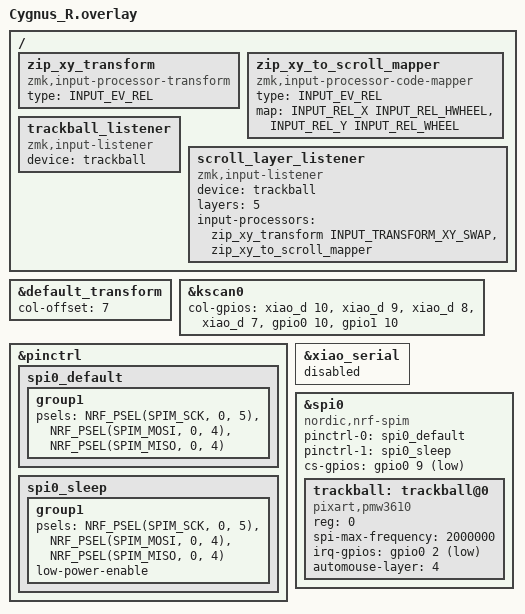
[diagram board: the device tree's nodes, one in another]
#include <dt-bindings/zmk/input_transform.h>
#include <dt-bindings/zmk/pointers.h>
#include <zephyr/dt-bindings/input/input-event-codes.h>
#include "Cygnus.dtsi"

&default_transform {
    col-offset = <7>;
};

&kscan0 {
    col-gpios
        = <&xiao_d 10 GPIO_ACTIVE_HIGH>
        , <&xiao_d 9 GPIO_ACTIVE_HIGH> 
        , <&xiao_d 8 GPIO_ACTIVE_HIGH> 
        , <&xiao_d 7 GPIO_ACTIVE_HIGH> 
        , <&gpio0 10 GPIO_ACTIVE_HIGH>
        , <&gpio1 10 GPIO_ACTIVE_HIGH>
        ;
};

/ {
    zip_xy_transform: zip_xy_transform {
        compatible = "zmk,input-processor-transform";
        #input-processor-cells = <1>;
        type = <INPUT_EV_REL>;
    };

    zip_xy_to_scroll_mapper: zip_xy_to_scroll_mapper {
        compatible = "zmk,input-processor-code-mapper";
        #input-processor-cells = <0>;
        type = <INPUT_EV_REL>;
        map = <INPUT_REL_X INPUT_REL_HWHEEL>, <INPUT_REL_Y INPUT_REL_WHEEL>;
    };

    trackball_listener {
        compatible = "zmk,input-listener";
        device = <&trackball>;
    };

    scroll_layer_listener {
        compatible = "zmk,input-listener";
        device = <&trackball>;
        layers = <5>;

        input-processors =
            <&zip_xy_transform INPUT_TRANSFORM_XY_SWAP>,
            <&zip_xy_to_scroll_mapper>;
    };
};

&pinctrl {
    spi0_default: spi0_default {
        group1 {
            psels = <NRF_PSEL(SPIM_SCK, 0, 5)>,
                <NRF_PSEL(SPIM_MOSI, 0, 4)>,
                <NRF_PSEL(SPIM_MISO, 0, 4)>;
        };
    };

    spi0_sleep: spi0_sleep {
        group1 {
            psels = <NRF_PSEL(SPIM_SCK, 0, 5)>,
                <NRF_PSEL(SPIM_MOSI, 0, 4)>,
                <NRF_PSEL(SPIM_MISO, 0, 4)>;
            low-power-enable;
        };
    };
};

&xiao_serial { status = "disabled"; };

&spi0 {
    status = "okay";
    compatible = "nordic,nrf-spim";
    pinctrl-0 = <&spi0_default>;
    pinctrl-1 = <&spi0_sleep>;
    pinctrl-names = "default", "sleep";
    cs-gpios = <&gpio0 9 GPIO_ACTIVE_LOW>;

    trackball: trackball@0 {
        status = "okay";
        compatible = "pixart,pmw3610";
        reg = <0>;
        spi-max-frequency = <2000000>;
        irq-gpios = <&gpio0 2 (GPIO_ACTIVE_LOW | GPIO_PULL_UP)>;
        automouse-layer = <4>;
        /* scroll-layers 属性を削除（scroll_layer_listener で処理するため） */
    };
};
